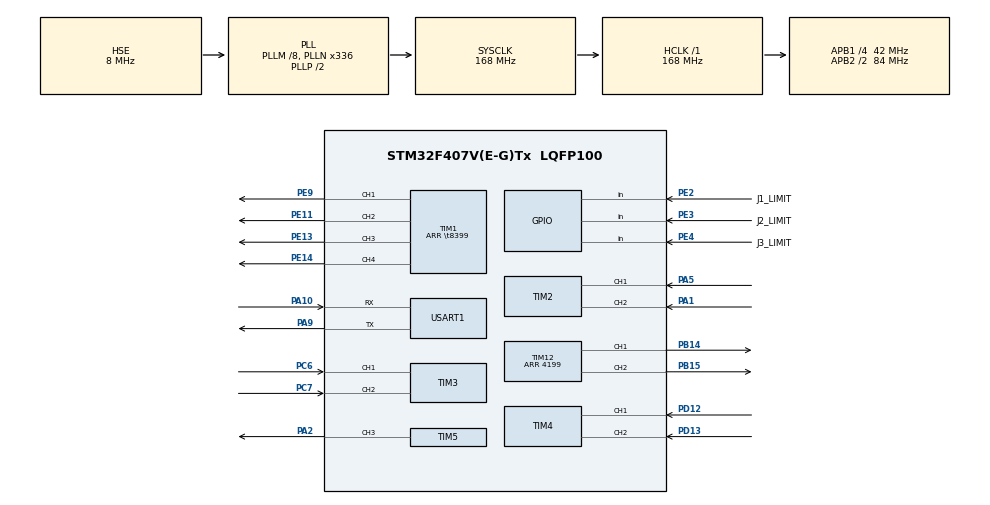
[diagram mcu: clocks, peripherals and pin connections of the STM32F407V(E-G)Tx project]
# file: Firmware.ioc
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Dma.Request0=USART1_RX
Dma.Request1=USART1_TX
Dma.USART1_RX.0.Direction=DMA_PERIPH_TO_MEMORY
Dma.USART1_RX.0.FIFOMode=DMA_FIFOMODE_DISABLE
Dma.USART1_RX.0.Instance=DMA2_Stream2
Dma.USART1_RX.0.MemDataAlignment=DMA_MDATAALIGN_BYTE
Dma.USART1_RX.0.MemInc=DMA_MINC_ENABLE
Dma.USART1_RX.0.Mode=DMA_CIRCULAR
Dma.USART1_RX.0.PeriphDataAlignment=DMA_PDATAALIGN_BYTE
Dma.USART1_RX.0.PeriphInc=DMA_PINC_DISABLE
Dma.USART1_RX.0.Priority=DMA_PRIORITY_HIGH
Dma.USART1_TX.1.Direction=DMA_MEMORY_TO_PERIPH
Dma.USART1_TX.1.FIFOMode=DMA_FIFOMODE_DISABLE
Dma.USART1_TX.1.Instance=DMA2_Stream7
Dma.USART1_TX.1.MemDataAlignment=DMA_MDATAALIGN_BYTE
Dma.USART1_TX.1.MemInc=DMA_MINC_ENABLE
Dma.USART1_TX.1.Mode=DMA_NORMAL
Dma.USART1_TX.1.PeriphDataAlignment=DMA_PDATAALIGN_BYTE
Dma.USART1_TX.1.PeriphInc=DMA_PINC_DISABLE
Dma.USART1_TX.1.Priority=DMA_PRIORITY_MEDIUM
FREERTOS.Tasks01=ControlTask,40,512,StartControlTask,Default,NULL,Dynamic,NULL,NULL;CommTask,32,512,StartCommTask,Default,NULL,Dynamic,NULL,NULL;RobotTask,24,512,StartRobotTask,Default,NULL,Dynamic,NULL,NULL;TelemetryTask,16,512,StartTelemetryTask,Default,NULL,Dynamic,NULL,NULL
FREERTOS.configCHECK_FOR_STACK_OVERFLOW=2
FREERTOS.configTOTAL_HEAP_SIZE=32768
FREERTOS.configUSE_MALLOC_FAILED_HOOK=1
Mcu.Family=STM32F4
Mcu.Name=STM32F407V(E-G)Tx
Mcu.Package=LQFP100
NVIC.DMA2_Stream2_IRQn=true\:6\:0\:true\:false\:true\:true\:false\:true\:true
NVIC.DMA2_Stream7_IRQn=true\:6\:0\:true\:false\:true\:true\:false\:true\:true
NVIC.PriorityGroup=NVIC_PRIORITYGROUP_4
NVIC.TIM6_DAC_IRQn=true\:5\:0\:false\:false\:true\:true\:true\:true\:true
NVIC.TIM7_IRQn=true\:15\:0\:false\:false\:true\:false\:false\:true\:true
NVIC.TimeBase=TIM7_IRQn
NVIC.TimeBaseIP=TIM7
NVIC.USART1_IRQn=true\:6\:0\:true\:false\:true\:true\:false\:true\:true
PA1.Signal=S_TIM2_CH2
PA10.Mode=Asynchronous
PA10.Signal=USART1_RX
PA13.Mode=Serial_Wire
PA13.Signal=SYS_JTMS-SWDIO
PA14.Mode=Serial_Wire
PA14.Signal=SYS_JTCK-SWCLK
PA2.Signal=S_TIM5_CH3
PA5.Signal=S_TIM2_CH1_ETR
PA9.Mode=Asynchronous
PA9.Signal=USART1_TX
PB14.Signal=S_TIM12_CH1
PB15.Signal=S_TIM12_CH2
PC6.Signal=S_TIM3_CH1
PC7.Signal=S_TIM3_CH2
PD12.Signal=S_TIM4_CH1
PD13.Signal=S_TIM4_CH2
PE11.Signal=S_TIM1_CH2
PE13.Signal=S_TIM1_CH3
PE14.Signal=S_TIM1_CH4
PE2.GPIO_Label=J1_LIMIT
PE2.GPIO_PuPd=GPIO_PULLUP
PE2.Signal=GPIO_Input
PE3.GPIO_Label=J2_LIMIT
PE3.GPIO_PuPd=GPIO_PULLUP
PE3.Signal=GPIO_Input
PE4.GPIO_Label=J3_LIMIT
PE4.GPIO_PuPd=GPIO_PULLUP
PE4.Signal=GPIO_Input
PE9.Signal=S_TIM1_CH1
PH0-OSC_IN.Mode=HSE-External-Oscillator
PH0-OSC_IN.Signal=RCC_OSC_IN
PH1-OSC_OUT.Mode=HSE-External-Oscillator
PH1-OSC_OUT.Signal=RCC_OSC_OUT
ProjectManager.HeapSize=0x200
ProjectManager.StackSize=0x400
ProjectManager.TargetToolchain=MDK-ARM V5.32
RCC.48MHZClocksFreq_Value=84000000
RCC.AHBFreq_Value=168000000
RCC.APB1CLKDivider=RCC_HCLK_DIV4
RCC.APB1Freq_Value=42000000
RCC.APB1TimFreq_Value=84000000
RCC.APB2CLKDivider=RCC_HCLK_DIV2
RCC.APB2Freq_Value=84000000
RCC.APB2TimFreq_Value=168000000
RCC.CortexFreq_Value=168000000
RCC.HCLKFreq_Value=168000000
RCC.HSE_VALUE=8000000
RCC.HSI_VALUE=16000000
RCC.LSE_VALUE=32768
RCC.PLLM=8
RCC.PLLN=336
RCC.PLLSourceVirtual=RCC_PLLSOURCE_HSE
RCC.SYSCLKFreq_VALUE=168000000
RCC.SYSCLKSource=RCC_SYSCLKSOURCE_PLLCLK
RCC.VCOOutputFreq_Value=336000000
SH.S_TIM12_CH1.0=TIM12_CH1,PWM Generation1 CH1
SH.S_TIM12_CH2.0=TIM12_CH2,PWM Generation2 CH2
SH.S_TIM1_CH1.0=TIM1_CH1,PWM Generation1 CH1
SH.S_TIM1_CH2.0=TIM1_CH2,PWM Generation2 CH2
SH.S_TIM1_CH3.0=TIM1_CH3,PWM Generation3 CH3
SH.S_TIM1_CH4.0=TIM1_CH4,PWM Generation4 CH4
SH.S_TIM2_CH1_ETR.0=TIM2_CH1,Encoder_Interface
SH.S_TIM2_CH2.0=TIM2_CH2,Encoder_Interface
SH.S_TIM3_CH1.0=TIM3_CH1,Encoder_Interface
SH.S_TIM3_CH2.0=TIM3_CH2,Encoder_Interface
SH.S_TIM4_CH1.0=TIM4_CH1,Encoder_Interface
SH.S_TIM4_CH2.0=TIM4_CH2,Encoder_Interface
SH.S_TIM5_CH3.0=TIM5_CH3,PWM Generation3 CH3
TIM1.AutoReloadPreload=TIM_AUTORELOAD_PRELOAD_ENABLE
TIM1.Channel-PWM\ Generation1\ CH1=TIM_CHANNEL_1
TIM1.Channel-PWM\ Generation2\ CH2=TIM_CHANNEL_2
TIM1.Channel-PWM\ Generation3\ CH3=TIM_CHANNEL_3
TIM1.Channel-PWM\ Generation4\ CH4=TIM_CHANNEL_4
TIM1.Period=\t8399
TIM12.AutoReloadPreload=TIM_AUTORELOAD_PRELOAD_ENABLE
TIM12.Channel-PWM\ Generation1\ CH1=TIM_CHANNEL_1
TIM12.Channel-PWM\ Generation2\ CH2=TIM_CHANNEL_2
TIM12.Period=4199
TIM2.EncoderMode=TIM_ENCODERMODE_TI12
TIM3.EncoderMode=TIM_ENCODERMODE_TI12
TIM4.EncoderMode=TIM_ENCODERMODE_TI12
TIM5.AutoReloadPreload=TIM_AUTORELOAD_PRELOAD_ENABLE
TIM5.Channel-PWM\ Generation3\ CH3=TIM_CHANNEL_3
TIM5.Period=\t19999
TIM5.Prescaler=83
TIM5.Pulse-PWM\ Generation3\ CH3=1500
TIM6.Period=999
TIM6.Prescaler=83
USART1.VirtualMode=VM_ASYNC
VP_FREERTOS_VS_CMSIS_V2.Mode=CMSIS_V2
VP_SYS_VS_tim7.Mode=TIM7
VP_TIM12_VS_ClockSourceINT.Mode=Internal
VP_TIM1_VS_ClockSourceINT.Mode=Internal
VP_TIM5_VS_ClockSourceINT.Mode=Internal
VP_TIM6_VS_ClockSourceINT.Mode=Enable_Timer
board=custom

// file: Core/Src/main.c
/* USER CODE BEGIN Header */
/**
  ******************************************************************************
  * @file           : main.c
  * @brief          : Main program body
  ******************************************************************************
  * @attention
  *
  * Copyright (c) 2026 STMicroelectronics.
  * All rights reserved.
  *
  * This software is licensed under terms that can be found in the LICENSE file
  * in the root directory of this software component.
  * If no LICENSE file comes with this software, it is provided AS-IS.
  *
  ******************************************************************************
  */
/* USER CODE END Header */
#include "main.h"
#include "cmsis_os.h"

/* USER CODE BEGIN Includes */
#include "control_task.h"
#include "communication_task.h"
#include "robot_task.h"
#include "telemetry_task.h"
#include "shared_data.h"
#include "bsp_timer.h"

/* USER CODE END Includes */

TIM_HandleTypeDef htim1;
TIM_HandleTypeDef htim2;
TIM_HandleTypeDef htim3;
TIM_HandleTypeDef htim4;
TIM_HandleTypeDef htim5;
TIM_HandleTypeDef htim6;
TIM_HandleTypeDef htim12;

UART_HandleTypeDef huart1;
DMA_HandleTypeDef hdma_usart1_rx;
DMA_HandleTypeDef hdma_usart1_tx;

/* Definitions for ControlTask */
osThreadId_t ControlTaskHandle;
const osThreadAttr_t ControlTask_attributes = {
  .name = "ControlTask",
  .stack_size = 512 * 4,
  .priority = (osPriority_t) osPriorityHigh,
};
/* Definitions for CommTask */
osThreadId_t CommTaskHandle;
const osThreadAttr_t CommTask_attributes = {
  .name = "CommTask",
  .stack_size = 512 * 4,
  .priority = (osPriority_t) osPriorityAboveNormal,
};
/* Definitions for RobotTask */
osThreadId_t RobotTaskHandle;
const osThreadAttr_t RobotTask_attributes = {
  .name = "RobotTask",
  .stack_size = 512 * 4,
  .priority = (osPriority_t) osPriorityNormal,
};
/* Definitions for TelemetryTask */
osThreadId_t TelemetryTaskHandle;
const osThreadAttr_t TelemetryTask_attributes = {
  .name = "TelemetryTask",
  .stack_size = 512 * 4,
  .priority = (osPriority_t) osPriorityBelowNormal,
};

void SystemClock_Config(void);
static void MX_GPIO_Init(void);
static void MX_DMA_Init(void);
static void MX_TIM1_Init(void);
static void MX_TIM2_Init(void);
static void MX_TIM3_Init(void);
static void MX_TIM4_Init(void);
static void MX_TIM5_Init(void);
static void MX_TIM12_Init(void);
static void MX_USART1_UART_Init(void);
static void MX_TIM6_Init(void);
void StartControlTask(void *argument);
void StartCommTask(void *argument);
void StartRobotTask(void *argument);
void StartTelemetryTask(void *argument);

int main(void)
{

  /* MCU Configuration--------------------------------------------------------*/

  /* Reset of all peripherals, Initializes the Flash interface and the Systick. */
  HAL_Init();

  /* Configure the system clock */
  SystemClock_Config();

  /* Initialize all configured peripherals */
  MX_GPIO_Init();
  MX_DMA_Init();
  MX_TIM1_Init();
  MX_TIM2_Init();
  MX_TIM3_Init();
  MX_TIM4_Init();
  MX_TIM5_Init();
  MX_TIM12_Init();
  MX_USART1_UART_Init();
  MX_TIM6_Init();

  /* Init scheduler */
  osKernelInitialize();

  /* USER CODE BEGIN RTOS_QUEUES */
  shared_data_initialize();
  /* add queues, ... */
  /* USER CODE END RTOS_QUEUES */

  /* Create the thread(s) */
  /* creation of ControlTask */
  ControlTaskHandle = osThreadNew(StartControlTask, NULL, &ControlTask_attributes);

  /* creation of CommTask */
  CommTaskHandle = osThreadNew(StartCommTask, NULL, &CommTask_attributes);

  /* creation of RobotTask */
  RobotTaskHandle = osThreadNew(StartRobotTask, NULL, &RobotTask_attributes);

  /* creation of TelemetryTask */
  TelemetryTaskHandle = osThreadNew(StartTelemetryTask, NULL, &TelemetryTask_attributes);

  /* Start scheduler */
  osKernelStart();

  /* We should never get here as control is now taken by the scheduler */

  /* Infinite loop */
  while (1)
  {

  }
}

void SystemClock_Config(void)
{
  RCC_OscInitTypeDef RCC_OscInitStruct = {0};
  RCC_ClkInitTypeDef RCC_ClkInitStruct = {0};

  /** Configure the main internal regulator output voltage
  */
  __HAL_RCC_PWR_CLK_ENABLE();
  __HAL_PWR_VOLTAGESCALING_CONFIG(PWR_REGULATOR_VOLTAGE_SCALE1);

  /** Initializes the RCC Oscillators according to the specified parameters
  * in the RCC_OscInitTypeDef structure.
  */
  RCC_OscInitStruct.OscillatorType = RCC_OSCILLATORTYPE_HSE;
  RCC_OscInitStruct.HSEState = RCC_HSE_ON;
  RCC_OscInitStruct.PLL.PLLState = RCC_PLL_ON;
  RCC_OscInitStruct.PLL.PLLSource = RCC_PLLSOURCE_HSE;
  RCC_OscInitStruct.PLL.PLLM = 8;
  RCC_OscInitStruct.PLL.PLLN = 336;
  RCC_OscInitStruct.PLL.PLLP = RCC_PLLP_DIV2;
  RCC_OscInitStruct.PLL.PLLQ = 4;
  if (HAL_RCC_OscConfig(&RCC_OscInitStruct) != HAL_OK)
  {
    Error_Handler();
  }

  /** Initializes the CPU, AHB and APB buses clocks
  */
  RCC_ClkInitStruct.ClockType = RCC_CLOCKTYPE_HCLK|RCC_CLOCKTYPE_SYSCLK
                              |RCC_CLOCKTYPE_PCLK1|RCC_CLOCKTYPE_PCLK2;
  RCC_ClkInitStruct.SYSCLKSource = RCC_SYSCLKSOURCE_PLLCLK;
  RCC_ClkInitStruct.AHBCLKDivider = RCC_SYSCLK_DIV1;
  RCC_ClkInitStruct.APB1CLKDivider = RCC_HCLK_DIV4;
  RCC_ClkInitStruct.APB2CLKDivider = RCC_HCLK_DIV2;

  if (HAL_RCC_ClockConfig(&RCC_ClkInitStruct, FLASH_LATENCY_5) != HAL_OK)
  {
    Error_Handler();
  }
}

static void MX_TIM1_Init(void)
{

  TIM_ClockConfigTypeDef sClockSourceConfig = {0};
  TIM_MasterConfigTypeDef sMasterConfig = {0};
  TIM_OC_InitTypeDef sConfigOC = {0};
  TIM_BreakDeadTimeConfigTypeDef sBreakDeadTimeConfig = {0};

  htim1.Instance = TIM1;
  htim1.Init.Prescaler = 0;
  htim1.Init.CounterMode = TIM_COUNTERMODE_UP;
  htim1.Init.Period = 8399;
  htim1.Init.ClockDivision = TIM_CLOCKDIVISION_DIV1;
  htim1.Init.RepetitionCounter = 0;
  htim1.Init.AutoReloadPreload = TIM_AUTORELOAD_PRELOAD_ENABLE;
  if (HAL_TIM_Base_Init(&htim1) != HAL_OK)
  {
    Error_Handler();
  }
  sClockSourceConfig.ClockSource = TIM_CLOCKSOURCE_INTERNAL;
  if (HAL_TIM_ConfigClockSource(&htim1, &sClockSourceConfig) != HAL_OK)
  {
    Error_Handler();
  }
  if (HAL_TIM_PWM_Init(&htim1) != HAL_OK)
  {
    Error_Handler();
  }
  sMasterConfig.MasterOutputTrigger = TIM_TRGO_RESET;
  sMasterConfig.MasterSlaveMode = TIM_MASTERSLAVEMODE_DISABLE;
  if (HAL_TIMEx_MasterConfigSynchronization(&htim1, &sMasterConfig) != HAL_OK)
  {
    Error_Handler();
  }
  sConfigOC.OCMode = TIM_OCMODE_PWM1;
  sConfigOC.Pulse = 0;
  sConfigOC.OCPolarity = TIM_OCPOLARITY_HIGH;
  sConfigOC.OCNPolarity = TIM_OCNPOLARITY_HIGH;
  sConfigOC.OCFastMode = TIM_OCFAST_DISABLE;
  sConfigOC.OCIdleState = TIM_OCIDLESTATE_RESET;
  sConfigOC.OCNIdleState = TIM_OCNIDLESTATE_RESET;
  if (HAL_TIM_PWM_ConfigChannel(&htim1, &sConfigOC, TIM_CHANNEL_1) != HAL_OK)
  {
    Error_Handler();
  }
  if (HAL_TIM_PWM_ConfigChannel(&htim1, &sConfigOC, TIM_CHANNEL_2) != HAL_OK)
  {
    Error_Handler();
  }
  if (HAL_TIM_PWM_ConfigChannel(&htim1, &sConfigOC, TIM_CHANNEL_3) != HAL_OK)
  {
    Error_Handler();
  }
  if (HAL_TIM_PWM_ConfigChannel(&htim1, &sConfigOC, TIM_CHANNEL_4) != HAL_OK)
  {
    Error_Handler();
  }
  sBreakDeadTimeConfig.OffStateRunMode = TIM_OSSR_DISABLE;
  sBreakDeadTimeConfig.OffStateIDLEMode = TIM_OSSI_DISABLE;
  sBreakDeadTimeConfig.LockLevel = TIM_LOCKLEVEL_OFF;
  sBreakDeadTimeConfig.DeadTime = 0;
  sBreakDeadTimeConfig.BreakState = TIM_BREAK_DISABLE;
  sBreakDeadTimeConfig.BreakPolarity = TIM_BREAKPOLARITY_HIGH;
  sBreakDeadTimeConfig.AutomaticOutput = TIM_AUTOMATICOUTPUT_DISABLE;
  if (HAL_TIMEx_ConfigBreakDeadTime(&htim1, &sBreakDeadTimeConfig) != HAL_OK)
  {
    Error_Handler();
  }
  HAL_TIM_MspPostInit(&htim1);

}

static void MX_TIM2_Init(void)
{

  TIM_Encoder_InitTypeDef sConfig = {0};
  TIM_MasterConfigTypeDef sMasterConfig = {0};

  htim2.Instance = TIM2;
  htim2.Init.Prescaler = 0;
  htim2.Init.CounterMode = TIM_COUNTERMODE_UP;
  htim2.Init.Period = 4294967295;
  htim2.Init.ClockDivision = TIM_CLOCKDIVISION_DIV1;
  htim2.Init.AutoReloadPreload = TIM_AUTORELOAD_PRELOAD_DISABLE;
  sConfig.EncoderMode = TIM_ENCODERMODE_TI12;
  sConfig.IC1Polarity = TIM_ICPOLARITY_RISING;
  sConfig.IC1Selection = TIM_ICSELECTION_DIRECTTI;
  sConfig.IC1Prescaler = TIM_ICPSC_DIV1;
  sConfig.IC1Filter = 0;
  sConfig.IC2Polarity = TIM_ICPOLARITY_RISING;
  sConfig.IC2Selection = TIM_ICSELECTION_DIRECTTI;
  sConfig.IC2Prescaler = TIM_ICPSC_DIV1;
  sConfig.IC2Filter = 0;
  if (HAL_TIM_Encoder_Init(&htim2, &sConfig) != HAL_OK)
  {
    Error_Handler();
  }
  sMasterConfig.MasterOutputTrigger = TIM_TRGO_RESET;
  sMasterConfig.MasterSlaveMode = TIM_MASTERSLAVEMODE_DISABLE;
  if (HAL_TIMEx_MasterConfigSynchronization(&htim2, &sMasterConfig) != HAL_OK)
  {
    Error_Handler();
  }

}

static void MX_TIM3_Init(void)
{

  TIM_Encoder_InitTypeDef sConfig = {0};
  TIM_MasterConfigTypeDef sMasterConfig = {0};

  htim3.Instance = TIM3;
  htim3.Init.Prescaler = 0;
  htim3.Init.CounterMode = TIM_COUNTERMODE_UP;
  htim3.Init.Period = 65535;
  htim3.Init.ClockDivision = TIM_CLOCKDIVISION_DIV1;
  htim3.Init.AutoReloadPreload = TIM_AUTORELOAD_PRELOAD_DISABLE;
  sConfig.EncoderMode = TIM_ENCODERMODE_TI12;
  sConfig.IC1Polarity = TIM_ICPOLARITY_RISING;
  sConfig.IC1Selection = TIM_ICSELECTION_DIRECTTI;
  sConfig.IC1Prescaler = TIM_ICPSC_DIV1;
  sConfig.IC1Filter = 0;
  sConfig.IC2Polarity = TIM_ICPOLARITY_RISING;
  sConfig.IC2Selection = TIM_ICSELECTION_DIRECTTI;
  sConfig.IC2Prescaler = TIM_ICPSC_DIV1;
  sConfig.IC2Filter = 0;
  if (HAL_TIM_Encoder_Init(&htim3, &sConfig) != HAL_OK)
  {
    Error_Handler();
  }
  sMasterConfig.MasterOutputTrigger = TIM_TRGO_RESET;
  sMasterConfig.MasterSlaveMode = TIM_MASTERSLAVEMODE_DISABLE;
  if (HAL_TIMEx_MasterConfigSynchronization(&htim3, &sMasterConfig) != HAL_OK)
  {
    Error_Handler();
  }

}

static void MX_TIM4_Init(void)
{

  TIM_Encoder_InitTypeDef sConfig = {0};
  TIM_MasterConfigTypeDef sMasterConfig = {0};

  htim4.Instance = TIM4;
  htim4.Init.Prescaler = 0;
  htim4.Init.CounterMode = TIM_COUNTERMODE_UP;
  htim4.Init.Period = 65535;
  htim4.Init.ClockDivision = TIM_CLOCKDIVISION_DIV1;
  htim4.Init.AutoReloadPreload = TIM_AUTORELOAD_PRELOAD_DISABLE;
  sConfig.EncoderMode = TIM_ENCODERMODE_TI12;
  sConfig.IC1Polarity = TIM_ICPOLARITY_RISING;
  sConfig.IC1Selection = TIM_ICSELECTION_DIRECTTI;
  sConfig.IC1Prescaler = TIM_ICPSC_DIV1;
  sConfig.IC1Filter = 0;
  sConfig.IC2Polarity = TIM_ICPOLARITY_RISING;
  sConfig.IC2Selection = TIM_ICSELECTION_DIRECTTI;
  sConfig.IC2Prescaler = TIM_ICPSC_DIV1;
  sConfig.IC2Filter = 0;
  if (HAL_TIM_Encoder_Init(&htim4, &sConfig) != HAL_OK)
  {
    Error_Handler();
  }
  sMasterConfig.MasterOutputTrigger = TIM_TRGO_RESET;
  sMasterConfig.MasterSlaveMode = TIM_MASTERSLAVEMODE_DISABLE;
  if (HAL_TIMEx_MasterConfigSynchronization(&htim4, &sMasterConfig) != HAL_OK)
  {
    Error_Handler();
  }

}

static void MX_TIM5_Init(void)
{

  TIM_ClockConfigTypeDef sClockSourceConfig = {0};
  TIM_MasterConfigTypeDef sMasterConfig = {0};
  TIM_OC_InitTypeDef sConfigOC = {0};

  htim5.Instance = TIM5;
  htim5.Init.Prescaler = 83;
  htim5.Init.CounterMode = TIM_COUNTERMODE_UP;
  htim5.Init.Period = 19999;
  htim5.Init.ClockDivision = TIM_CLOCKDIVISION_DIV1;
  htim5.Init.AutoReloadPreload = TIM_AUTORELOAD_PRELOAD_ENABLE;
  if (HAL_TIM_Base_Init(&htim5) != HAL_OK)
  {
    Error_Handler();
  }
  sClockSourceConfig.ClockSource = TIM_CLOCKSOURCE_INTERNAL;
  if (HAL_TIM_ConfigClockSource(&htim5, &sClockSourceConfig) != HAL_OK)
  {
    Error_Handler();
  }
  if (HAL_TIM_PWM_Init(&htim5) != HAL_OK)
  {
    Error_Handler();
  }
  sMasterConfig.MasterOutputTrigger = TIM_TRGO_RESET;
  sMasterConfig.MasterSlaveMode = TIM_MASTERSLAVEMODE_DISABLE;
  if (HAL_TIMEx_MasterConfigSynchronization(&htim5, &sMasterConfig) != HAL_OK)
  {
    Error_Handler();
  }
  sConfigOC.OCMode = TIM_OCMODE_PWM1;
  sConfigOC.Pulse = 1500;
  sConfigOC.OCPolarity = TIM_OCPOLARITY_HIGH;
  sConfigOC.OCFastMode = TIM_OCFAST_DISABLE;
  if (HAL_TIM_PWM_ConfigChannel(&htim5, &sConfigOC, TIM_CHANNEL_3) != HAL_OK)
  {
    Error_Handler();
  }
  HAL_TIM_MspPostInit(&htim5);

}

static void MX_TIM6_Init(void)
{

  TIM_MasterConfigTypeDef sMasterConfig = {0};

  htim6.Instance = TIM6;
  htim6.Init.Prescaler = 83;
  htim6.Init.CounterMode = TIM_COUNTERMODE_UP;
  htim6.Init.Period = 999;
  htim6.Init.AutoReloadPreload = TIM_AUTORELOAD_PRELOAD_DISABLE;
  if (HAL_TIM_Base_Init(&htim6) != HAL_OK)
  {
    Error_Handler();
  }
  sMasterConfig.MasterOutputTrigger = TIM_TRGO_RESET;
  sMasterConfig.MasterSlaveMode = TIM_MASTERSLAVEMODE_DISABLE;
  if (HAL_TIMEx_MasterConfigSynchronization(&htim6, &sMasterConfig) != HAL_OK)
  {
    Error_Handler();
  }

}

static void MX_TIM12_Init(void)
{

  TIM_ClockConfigTypeDef sClockSourceConfig = {0};
  TIM_OC_InitTypeDef sConfigOC = {0};

  htim12.Instance = TIM12;
  htim12.Init.Prescaler = 0;
  htim12.Init.CounterMode = TIM_COUNTERMODE_UP;
  htim12.Init.Period = 4199;
  htim12.Init.ClockDivision = TIM_CLOCKDIVISION_DIV1;
  htim12.Init.AutoReloadPreload = TIM_AUTORELOAD_PRELOAD_ENABLE;
  if (HAL_TIM_Base_Init(&htim12) != HAL_OK)
  {
    Error_Handler();
  }
  sClockSourceConfig.ClockSource = TIM_CLOCKSOURCE_INTERNAL;
  if (HAL_TIM_ConfigClockSource(&htim12, &sClockSourceConfig) != HAL_OK)
  {
    Error_Handler();
  }
  if (HAL_TIM_PWM_Init(&htim12) != HAL_OK)
  {
    Error_Handler();
  }
  sConfigOC.OCMode = TIM_OCMODE_PWM1;
  sConfigOC.Pulse = 0;
  sConfigOC.OCPolarity = TIM_OCPOLARITY_HIGH;
  sConfigOC.OCFastMode = TIM_OCFAST_DISABLE;
  if (HAL_TIM_PWM_ConfigChannel(&htim12, &sConfigOC, TIM_CHANNEL_1) != HAL_OK)
  {
    Error_Handler();
  }
  if (HAL_TIM_PWM_ConfigChannel(&htim12, &sConfigOC, TIM_CHANNEL_2) != HAL_OK)
  {
    Error_Handler();
  }
  HAL_TIM_MspPostInit(&htim12);

}

static void MX_USART1_UART_Init(void)
{

  huart1.Instance = USART1;
  huart1.Init.BaudRate = 115200;
  huart1.Init.WordLength = UART_WORDLENGTH_8B;
  huart1.Init.StopBits = UART_STOPBITS_1;
  huart1.Init.Parity = UART_PARITY_NONE;
  huart1.Init.Mode = UART_MODE_TX_RX;
  huart1.Init.HwFlowCtl = UART_HWCONTROL_NONE;
  huart1.Init.OverSampling = UART_OVERSAMPLING_16;
  if (HAL_UART_Init(&huart1) != HAL_OK)
  {
    Error_Handler();
  }

}

static void MX_DMA_Init(void)
{

  /* DMA controller clock enable */
  __HAL_RCC_DMA2_CLK_ENABLE();

  /* DMA interrupt init */
  /* DMA2_Stream2_IRQn interrupt configuration */
  HAL_NVIC_SetPriority(DMA2_Stream2_IRQn, 6, 0);
  HAL_NVIC_EnableIRQ(DMA2_Stream2_IRQn);
  /* DMA2_Stream7_IRQn interrupt configuration */
  HAL_NVIC_SetPriority(DMA2_Stream7_IRQn, 6, 0);
  HAL_NVIC_EnableIRQ(DMA2_Stream7_IRQn);

}

static void MX_GPIO_Init(void)
{
  GPIO_InitTypeDef GPIO_InitStruct = {0};

  /* GPIO Ports Clock Enable */
  __HAL_RCC_GPIOE_CLK_ENABLE();
  __HAL_RCC_GPIOH_CLK_ENABLE();
  __HAL_RCC_GPIOA_CLK_ENABLE();
  __HAL_RCC_GPIOB_CLK_ENABLE();
  __HAL_RCC_GPIOD_CLK_ENABLE();
  __HAL_RCC_GPIOC_CLK_ENABLE();

  /*Configure GPIO pins : J1_LIMIT_Pin J2_LIMIT_Pin J3_LIMIT_Pin */
  GPIO_InitStruct.Pin = J1_LIMIT_Pin|J2_LIMIT_Pin|J3_LIMIT_Pin;
  GPIO_InitStruct.Mode = GPIO_MODE_INPUT;
  GPIO_InitStruct.Pull = GPIO_PULLUP;
  HAL_GPIO_Init(GPIOE, &GPIO_InitStruct);

}

void StartControlTask(void *argument)
{
  /* USER CODE BEGIN 5 */
  control_task_run(argument);
  /* USER CODE END 5 */
}

void StartCommTask(void *argument)
{
  /* USER CODE BEGIN StartCommTask */
  communication_task_run(argument);
  /* USER CODE END StartCommTask */
}

void StartRobotTask(void *argument)
{
  /* USER CODE BEGIN StartRobotTask */
  robot_task_run(argument);
  /* USER CODE END StartRobotTask */
}

void StartTelemetryTask(void *argument)
{
  /* USER CODE BEGIN StartTelemetryTask */
  telemetry_task_run(argument);
  /* USER CODE END StartTelemetryTask */
}

void HAL_TIM_PeriodElapsedCallback(TIM_HandleTypeDef *htim)
{
  if (htim->Instance == TIM7)
  {
    HAL_IncTick();
  }
  /* USER CODE BEGIN Callback 1 */
  bsp_timer_on_period_elapsed(htim);

  /* USER CODE END Callback 1 */
}

void Error_Handler(void)
{
  __disable_irq();
  while (1)
  {
  }
}
